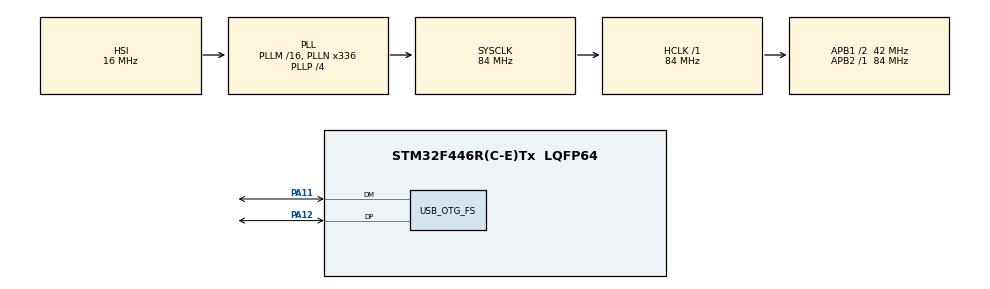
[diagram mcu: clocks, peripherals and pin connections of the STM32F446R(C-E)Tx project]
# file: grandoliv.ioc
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Mcu.Family=STM32F4
Mcu.Name=STM32F446R(C-E)Tx
Mcu.Package=LQFP64
NVIC.OTG_FS_IRQn=true\:0\:0\:false\:false\:true\:false\:true
NVIC.PriorityGroup=NVIC_PRIORITYGROUP_0
PA11.Mode=Device_Only
PA11.Signal=USB_OTG_FS_DM
PA12.Mode=Device_Only
PA12.Signal=USB_OTG_FS_DP
ProjectManager.HeapSize=0x200
ProjectManager.StackSize=0x400
ProjectManager.TargetToolchain=STM32CubeIDE
RCC.48MHZClocksFreq_Value=84000000
RCC.AHBFreq_Value=84000000
RCC.APB1CLKDivider=RCC_HCLK_DIV2
RCC.APB1Freq_Value=42000000
RCC.APB1TimFreq_Value=84000000
RCC.APB2Freq_Value=84000000
RCC.APB2TimFreq_Value=84000000
RCC.CortexFreq_Value=84000000
RCC.FLatency-AdvancedSettings=FLASH_LATENCY_2
RCC.HCLKFreq_Value=84000000
RCC.HSE_VALUE=8000000
RCC.HSI_VALUE=16000000
RCC.PLLN=336
RCC.PLLP=RCC_PLLP_DIV4
RCC.PLLQ=7
RCC.PLLSourceVirtualString=RCC_PLLSOURCE_HSI
RCC.SYSCLKFreq_VALUE=84000000
RCC.SYSCLKSource=RCC_SYSCLKSOURCE_PLLCLK
RCC.USBFreq_Value=48000000
RCC.VCOOutputFreq_Value=336000000
USB_DEVICE.CLASS_NAME_FS=AUDIO
USB_DEVICE.VirtualMode-AUDIO_FS=Audio
USB_DEVICE.VirtualModeFS=Audio_FS
USB_OTG_FS.VirtualMode=Device_Only
VP_USB_DEVICE_VS_USB_DEVICE_AUDIO_FS.Mode=AUDIO_FS
board=NUCLEO-F446RE

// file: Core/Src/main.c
/* USER CODE BEGIN Header */
/**
  ******************************************************************************
  * @file           : main.c
  * @brief          : Main program body
  ******************************************************************************
  * @attention
  *
  * <h2><center>&copy; Copyright (c) 2020 STMicroelectronics.
  * All rights reserved.</center></h2>
  *
  * This software component is licensed by ST under BSD 3-Clause license,
  * the "License"; You may not use this file except in compliance with the
  * License. You may obtain a copy of the License at:
  *                        opensource.org/licenses/BSD-3-Clause
  *
  ******************************************************************************
  */
/* USER CODE END Header */

#include "main.h"
#include "usb_device.h"

/* USER CODE BEGIN Includes */
#include "usbd_core.h"
#include "usbd_MIDI.h"
#include "usbd_midi_if.h"
/* USER CODE END Includes */

/* USER CODE BEGIN PV */
uint8_t msgnum, midimsg, received_char, key, velocity, ctrl, data;
/* USER CODE END PV */

void SystemClock_Config(void);
static void MX_GPIO_Init(void);

int main(void)
{

  /* MCU Configuration--------------------------------------------------------*/

  /* Reset of all peripherals, Initializes the Flash interface and the Systick. */
  HAL_Init();

  /* Configure the system clock */
  SystemClock_Config();

  /* Initialize all configured peripherals */
  MX_GPIO_Init();
  MX_USB_DEVICE_Init();

  /* Infinite loop */
  while (1)
  {

  }
}

void SystemClock_Config(void)
{
  RCC_OscInitTypeDef RCC_OscInitStruct = {0};
  RCC_ClkInitTypeDef RCC_ClkInitStruct = {0};
  RCC_PeriphCLKInitTypeDef PeriphClkInitStruct = {0};

  /** Configure the main internal regulator output voltage
  */
  __HAL_RCC_PWR_CLK_ENABLE();
  __HAL_PWR_VOLTAGESCALING_CONFIG(PWR_REGULATOR_VOLTAGE_SCALE3);
  /** Initializes the CPU, AHB and APB busses clocks
  */
  RCC_OscInitStruct.OscillatorType = RCC_OSCILLATORTYPE_HSI;
  RCC_OscInitStruct.HSIState = RCC_HSI_ON;
  RCC_OscInitStruct.HSICalibrationValue = RCC_HSICALIBRATION_DEFAULT;
  RCC_OscInitStruct.PLL.PLLState = RCC_PLL_ON;
  RCC_OscInitStruct.PLL.PLLSource = RCC_PLLSOURCE_HSI;
  RCC_OscInitStruct.PLL.PLLM = 16;
  RCC_OscInitStruct.PLL.PLLN = 336;
  RCC_OscInitStruct.PLL.PLLP = RCC_PLLP_DIV4;
  RCC_OscInitStruct.PLL.PLLQ = 7;
  RCC_OscInitStruct.PLL.PLLR = 2;
  if (HAL_RCC_OscConfig(&RCC_OscInitStruct) != HAL_OK)
  {
    Error_Handler();
  }
  /** Initializes the CPU, AHB and APB busses clocks
  */
  RCC_ClkInitStruct.ClockType = RCC_CLOCKTYPE_HCLK|RCC_CLOCKTYPE_SYSCLK
                              |RCC_CLOCKTYPE_PCLK1|RCC_CLOCKTYPE_PCLK2;
  RCC_ClkInitStruct.SYSCLKSource = RCC_SYSCLKSOURCE_PLLCLK;
  RCC_ClkInitStruct.AHBCLKDivider = RCC_SYSCLK_DIV1;
  RCC_ClkInitStruct.APB1CLKDivider = RCC_HCLK_DIV2;
  RCC_ClkInitStruct.APB2CLKDivider = RCC_HCLK_DIV1;

  if (HAL_RCC_ClockConfig(&RCC_ClkInitStruct, FLASH_LATENCY_2) != HAL_OK)
  {
    Error_Handler();
  }
  PeriphClkInitStruct.PeriphClockSelection = RCC_PERIPHCLK_CLK48;
  PeriphClkInitStruct.Clk48ClockSelection = RCC_CLK48CLKSOURCE_PLLQ;
  if (HAL_RCCEx_PeriphCLKConfig(&PeriphClkInitStruct) != HAL_OK)
  {
    Error_Handler();
  }
}

static void MX_GPIO_Init(void)
{

  /* GPIO Ports Clock Enable */
  __HAL_RCC_GPIOA_CLK_ENABLE();

}

/* USER CODE BEGIN 4 */
//void USARTx_CharReception_Callback(void)
//{
//	__IO uint32_t received_char;
//
//  /* Read Received character. RXNE flag is cleared by reading of RDR register */
//  received_char = LL_USART_ReceiveData8(USARTx_INSTANCE);
//
//	if(msgnum == 0)
//	{
//		midimsg = received_char;
//	}
//	if(msgnum == 1)
//	{
//		key = received_char;
//		ctrl = received_char;
//	}
//	if(msgnum == 2)
//	{
//		velocity = received_char;
//		data = received_char;
//	}
//
//	msgnum++;
//
//	if(msgnum == 3)
//	{
//		msgnum = 0;
//		ProcessReceivedMidiDatas();
//	}
//}
//
///**
//  * @brief  Function called in case of error detected in USART IT Handler
//  * @param  None
//  * @retval None
//  */
//void Error_Callback(void)
//{
//	LL_USART_ClearFlag_FE(USARTx_INSTANCE);
//	msgnum = 0;
//}
//
//void SendToUSART(uint8_t midichar)
//{
//	/* Send the packet thru host serial TX */
//	LL_USART_TransmitData8(USARTx_INSTANCE, midichar);
//	/* Wait for TXE flag to be raised */
//  while (!LL_USART_IsActiveFlag_TXE(USARTx_INSTANCE))
//	{
//	}
//}
/* USER CODE END 4 */

void Error_Handler(void)
{
}

/************************ (C) COPYRIGHT STMicroelectronics *****END OF FILE****/
